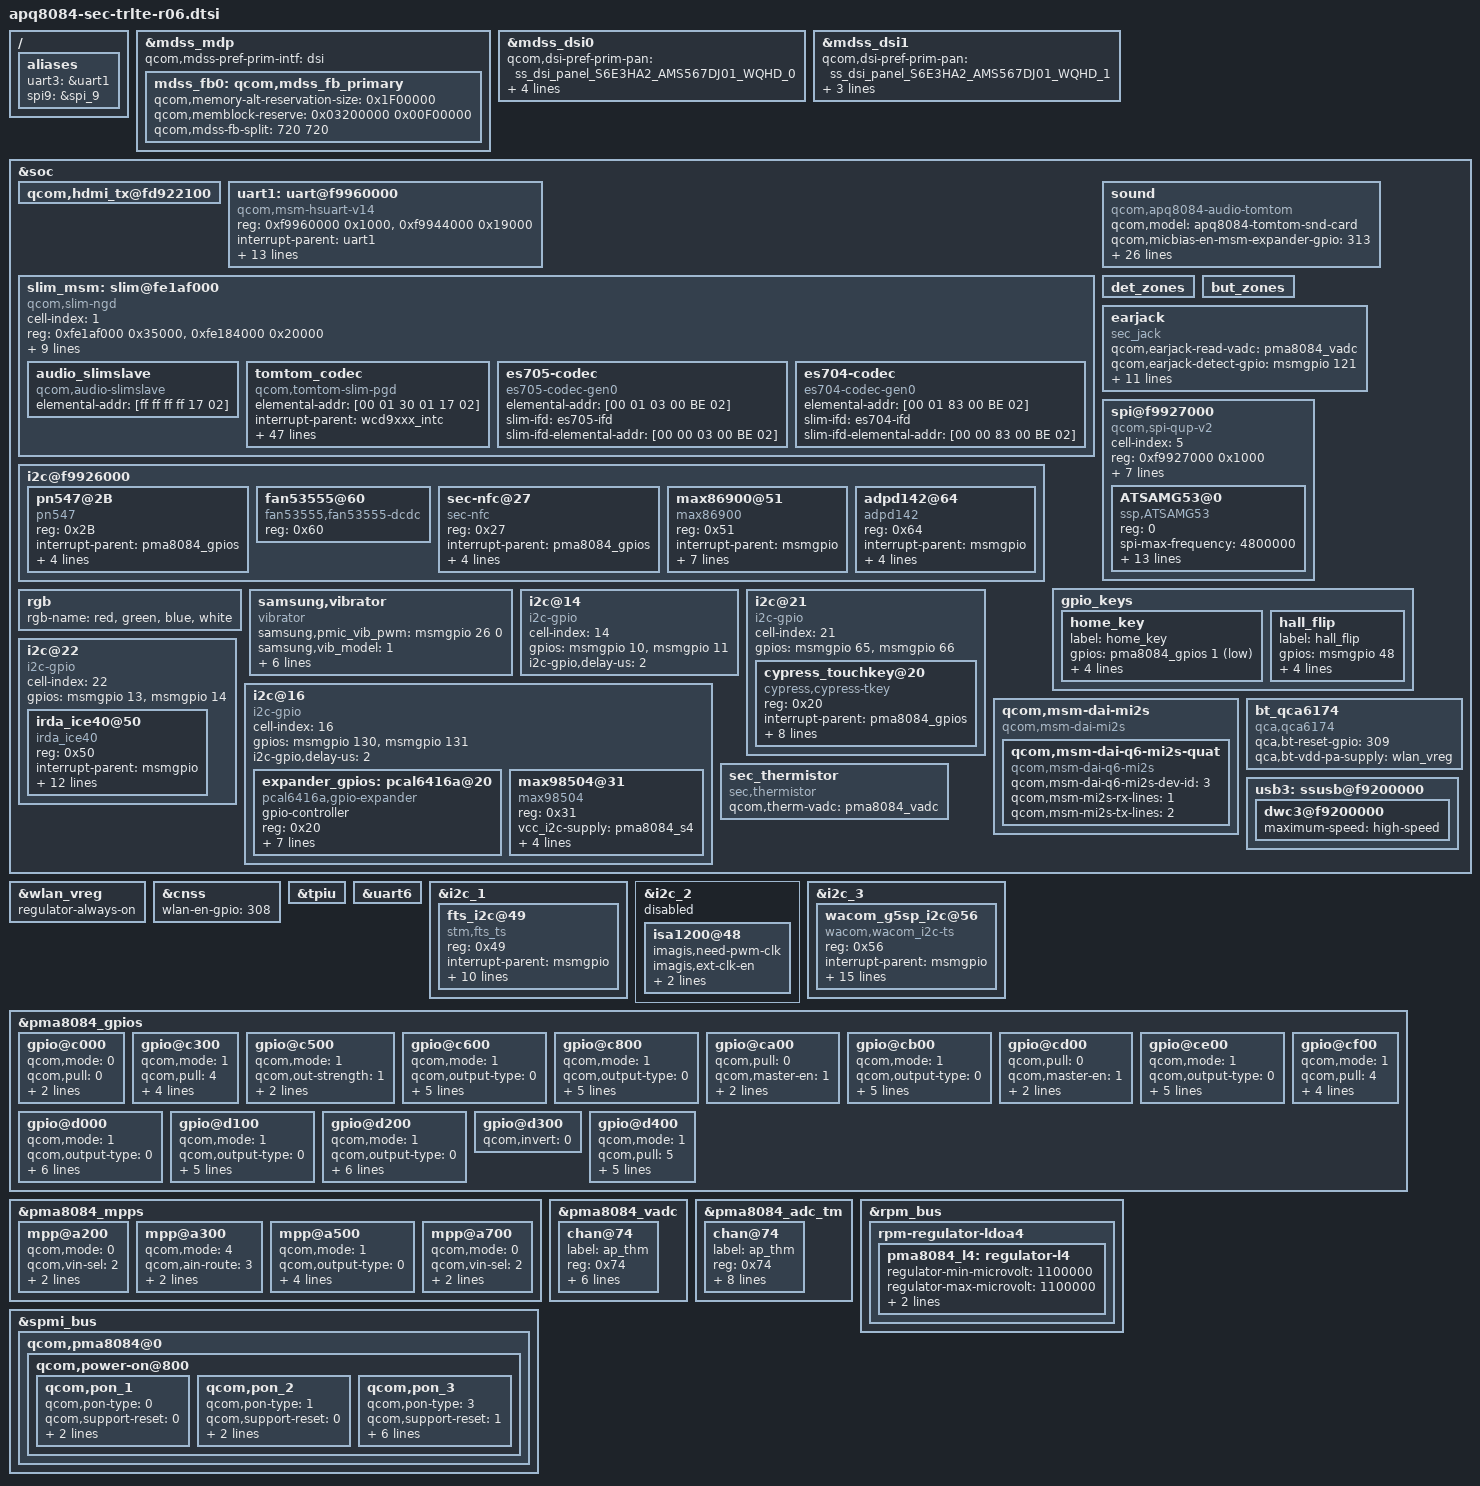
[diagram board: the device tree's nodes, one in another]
/* Copyright (c) 2013-2014, The Linux Foundation. All rights reserved.
 *
 * This program is free software; you can redistribute it and/or modify
 * it under the terms of the GNU General Public License version 2 and
 * only version 2 as published by the Free Software Foundation.
 *
 * This program is distributed in the hope that it will be useful,
 * but WITHOUT ANY WARRANTY; without even the implied warranty of
 * MERCHANTABILITY or FITNESS FOR A PARTICULAR PURPOSE.  See the
 * GNU General Public License for more details.
 */

/*
 * There are situations where removing properties or nodes may be useful.
 * syntax to do that:
 *   / {
 *       /delete-property/ propname;
 *       /delete-node/ nodename;
 *   };
 * or:
 *   /delete-node/ &noderef;
 */

#include "apq8084-camera-sensor-trlte-r04.dtsi"
#include "apq8084-max77843.dtsi"
#include "apq8084-w1-t-v1.dtsi"
#include "apq8084-fingerprint-sensor-trlte-r03.dtsi"

/ {
	aliases {
		uart3 = &uart1;
		spi9 = &spi_9;
	};
};

#include "../../../../drivers/video/msm/mdss/samsung/S6E3HA2_AMS567DJ01/dsi_panel_S6E3HA2_AMS567DJ01_wqhd_octa_cmd.dtsi"

&mdss_mdp {
		qcom,mdss-pref-prim-intf = "dsi";

		mdss_fb0: qcom,mdss_fb_primary {
			qcom,memory-alt-reservation-size = <0x1F00000>;
			qcom,memblock-reserve = <0x03200000 0x00F00000>;
			qcom,mdss-fb-split = <720 720>;
		};
	};

&mdss_dsi0 {
	qcom,dsi-pref-prim-pan = <&ss_dsi_panel_S6E3HA2_AMS567DJ01_WQHD_0>;
	qcom,platform-te-gpio = <&msmgpio 12 0>;

	/*qcom,dsi-panel-bias-vreg;*/
	qcom,platform-enable-gpio = <&pma8084_gpios 6 0>;
	qcom,platform-reset-gpio = <&pma8084_gpios 21 0>;

	iovdd-supply = <&pma8084_l26>;
};

&mdss_dsi1 {
	qcom,dsi-pref-prim-pan = <&ss_dsi_panel_S6E3HA2_AMS567DJ01_WQHD_1>;

	/*qcom,dsi-panel-bias-vreg;*/
	qcom,platform-enable-gpio = <&pma8084_gpios 6 0>;
	qcom,platform-reset-gpio = <&pma8084_gpios 21 0>;

	iovdd-supply = <&pma8084_l26>;
};

&soc {
	qcom,hdmi_tx@fd922100 {
		status = "ok";
	};

	uart1: uart@f9960000 {
		compatible = "qcom,msm-hsuart-v14";
		status = "ok";
		reg = <0xf9960000 0x1000>,
			<0xf9944000 0x19000>;
		reg-names = "core_mem", "bam_mem";
		interrupt-names = "core_irq", "bam_irq", "wakeup_irq";
	#address-cells = <0>;
		interrupt-parent = <&uart1>;
		interrupts = <0 1 2>;
	#interrupt-cells = <1>;
		interrupt-map-mask = <0xffffffff>;
		interrupt-map = <0 &intc 0 116 0 1 &intc 0 239 0 2 &msmgpio 60 0>;
		qcom,tx-gpio = <&msmgpio 59 0x00>;
		qcom,rx-gpio = <&msmgpio 60 0x00>;
		qcom,bam-tx-ep-pipe-index = <6>;
		qcom,bam-rx-ep-pipe-index = <7>;
		qcom,msm-bus,name = "uart1";
		qcom,msm-bus,num-cases = <2>;
		qcom,msm-bus,num-paths = <1>;
		qcom,msm-bus,vectors-KBps = <84 512 0 0>, <84 512 500 800>;
	};

	slim_msm: slim@fe1af000 {
		cell-index = <1>;
		compatible = "qcom,slim-ngd";
		reg = <0xfe1af000 0x35000>,
		      <0xfe184000 0x20000>;
		reg-names = "slimbus_physical", "slimbus_bam_physical";
		interrupts = <0 163 0>, <0 164 0>;
		interrupt-names = "slimbus_irq", "slimbus_bam_irq";
		qcom,apps-ch-pipes = <0x60000000>;
		qcom,ea-pc = <0xb0>;
		qcom,slim-mdm = "esoc0";

		audio_slimslave {
			compatible = "qcom,audio-slimslave";
			elemental-addr = [ff ff ff ff 17 02];
		};

		/delete-node/ taiko_codec;

		tomtom_codec {
			compatible = "qcom,tomtom-slim-pgd";
			elemental-addr = [00 01 30 01 17 02];

			interrupt-parent = <&wcd9xxx_intc>;
			interrupts = <0 1 2 3 4 5 6 7 8 9 10 11 12 13 14 15 16
				      17 18 19 20 21 22 23 24 25 26 27 28 30 31>;

			qcom,cdc-reset-gpio = <&msmgpio 101 0>;

			cdc-vdd-buck-supply = <&pma8084_s5>;
			qcom,cdc-vdd-buck-voltage = <2150000 2150000>;
			qcom,cdc-vdd-buck-current = <650000>;

			cdc-vdd-tx-h-supply = <&pma8084_s4>;
			qcom,cdc-vdd-tx-h-voltage = <1800000 1800000>;
			qcom,cdc-vdd-tx-h-current = <25000>;

			cdc-vdd-rx-h-supply = <&pma8084_s4>;
			qcom,cdc-vdd-rx-h-voltage = <1800000 1800000>;
			qcom,cdc-vdd-rx-h-current = <25000>;

			cdc-vddpx-1-supply = <&pma8084_s4>;
			qcom,cdc-vddpx-1-voltage = <1800000 1800000>;
			qcom,cdc-vddpx-1-current = <10000>;

			cdc-vdd-a-1p2v-supply = <&pma8084_l1>;
			qcom,cdc-vdd-a-1p2v-voltage = <1225000 1225000>;
			qcom,cdc-vdd-a-1p2v-current = <10000>;

			cdc-vddcx-1-supply = <&pma8084_l1>;
			qcom,cdc-vddcx-1-voltage = <1225000 1225000>;
			qcom,cdc-vddcx-1-current = <10000>;

			cdc-vddcx-2-supply = <&pma8084_l1>;
			qcom,cdc-vddcx-2-voltage = <1225000 1225000>;
			qcom,cdc-vddcx-2-current = <10000>;

			qcom,cdc-static-supplies = "cdc-vdd-buck",
						   "cdc-vdd-tx-h",
						   "cdc-vdd-rx-h",
						   "cdc-vddpx-1",
						   "cdc-vdd-a-1p2v",
						   "cdc-vddcx-1",
						   "cdc-vddcx-2";

			qcom,cdc-micbias-ldoh-v = <0x3>;
			qcom,cdc-micbias-cfilt1-mv = <1800>;
			qcom,cdc-micbias-cfilt2-mv = <2700>;
			qcom,cdc-micbias-cfilt3-mv = <1800>;
			qcom,cdc-micbias1-cfilt-sel = <0x0>;
			qcom,cdc-micbias2-cfilt-sel = <0x1>;
			qcom,cdc-micbias3-cfilt-sel = <0x2>;
			qcom,cdc-micbias4-cfilt-sel = <0x2>;
			qcom,cdc-mclk-clk-rate = <9600000>;
			qcom,cdc-slim-ifd = "tomtom-slim-ifd";
			qcom,cdc-slim-ifd-elemental-addr = [00 00 30 01 17 02];
			qcom,cdc-dmic-sample-rate = <4800000>;
			qcom,cdc-variant = "WCD9330";
		};
	};

	sound {
		compatible = "qcom,apq8084-audio-tomtom";
		qcom,model = "apq8084-tomtom-snd-card";
		qcom,micbias-en-msm-expander-gpio = <313>;

		qcom,audio-routing =
			"RX_BIAS", "MCLK",
			"LDO_H", "MCLK",
			"AIF4 MAD", "MCLK",
			"AMIC2", "MIC BIAS2 External",
			"MIC BIAS2 External", "Headset Mic",
			"DMIC1", "MIC BIAS1 External",
			"MIC BIAS1 External", "Digital Mic1",
			"DMIC2", "Main Mic Bias",
			"Main Mic Bias", "Main Mic",
			"DMIC3", "MIC BIAS3 External",
			"MIC BIAS3 External", "Digital Mic3",
			"DMIC4", "MIC BIAS1 External",
			"MIC BIAS1 External", "Sub Mic",
			"DMIC5", "MIC BIAS4 External",
			"MIC BIAS4 External", "Digital Mic5",
			"DMIC6", "MIC BIAS3 External",
			"MIC BIAS3 External", "Third Mic";

		qcom,codec-mclk-clk-freq = <9600000>;
		qcom,prim-auxpcm-gpio-clk  = <&msmgpio 87 0>;
		qcom,prim-auxpcm-gpio-sync = <&msmgpio 88 0>;
		qcom,prim-auxpcm-gpio-din  = <&msmgpio 89 0>;
		qcom,prim-auxpcm-gpio-dout = <&msmgpio 90 0>;
		qcom,prim-auxpcm-gpio-set = "prim-gpio-tert";
		qcom,sec-auxpcm-gpio-clk  = <&msmgpio 82 0>;
		qcom,sec-auxpcm-gpio-sync = <&msmgpio 83 0>;
		qcom,sec-auxpcm-gpio-dout = <&msmgpio 85 0>;
		qcom,cdc-micbias2-headset-only;
		qcom,ext-mclk-gpio  = <&msmgpio 47 0>;
		qcom,hdmi-audio-rx;
		qcom,maxim-mi2s-tx;
	};

	det_zones: det_zones {
		#list-det-cells = <4>;
	};

	but_zones: but_zones {
		#list-but-cells = <3>;
	};

	earjack {
		compatible = "sec_jack";
		qcom,earjack-read-vadc = <&pma8084_vadc>;
		qcom,earjack-detect-gpio = <&msmgpio 121 0>;
		qcom,earjack-micbias-expander-gpio = <312>;
		qcom,earjack-sendend-gpio = <&pma8084_gpios 4 0>;
		qcom,earjack-fsa_en-expander-gpio = <310>;
		qcom,send-end-active-high;
		det-zones-list = <&det_zones 3 10000 10 0>,
						 <&det_zones 930 10000 10 0>,
						 <&det_zones 2400 10000 10 1>,
						 <&det_zones 9999 10000 10 1>;
		but-zones-list = <&but_zones 0 0 145>,
						 <&but_zones 1 146 310>,
						 <&but_zones 2 311 640>;
		mpp-channel-scaling = <4 1 3>;
	};

	i2c@f9926000 { /* BLSP1 QUP4 */
		/delete-node/ nfc-nci@0e;

		pn547@2B {
			compatible = "pn547";
			reg = <0x2B>;
			interrupt-parent = <&pma8084_gpios>;
			interrupts = <11 0>;
			pn547,irq-gpio = <&pma8084_gpios 11 0>;
			pn547,ven-gpio = <&pma8084_mpps 5 0>;
			pn547,firm-expander-gpio = <311>;
		};
		fan53555@60 {
			compatible = "fan53555,fan53555-dcdc";
			reg = <0x60>;
		};

		sec-nfc@27 {
			compatible = "sec-nfc";
			reg = <0x27>;
			interrupt-parent = <&pma8084_gpios>;
			interrupts = <11 0>;
			sec-nfc,irq-gpio = <&pma8084_gpios 11 0>;
			sec-nfc,ven-gpio = <&pma8084_mpps 5 0>;
			sec-nfc,firm-expander-gpio = <311>;
		};

		max86900@51 {
			compatible = "max86900";
			reg = <0x51>;
			interrupt-parent = <&msmgpio>;
			interrupts = <78 0>;
			hrm_vreg-supply = <&pma8084_l16>;
			max86900,hrm_int-gpio = <&msmgpio 78 0x00>;
			max86900,vdd_1p8 = "max77826_ldo4";
			max86900,led_3p3 = "8084_l16";
			max86900,hrm_en-expander-gpio = <303>;
			max86900,dual-hrm = <1>;
		};

		adpd142@64 {
			compatible = "adpd142";
			reg = <0x64>;
			interrupt-parent = <&msmgpio>;
			interrupts = <78 0>;
			adpd142,irq_gpio = <&msmgpio 78 0x00>;
			adpd142,led_en = <301>;
			adpd142,vdd_1p8 = "max77826_ldo4";
		};
	};

	spi@f9927000 {
		compatible = "qcom,spi-qup-v2";
		cell-index = <5>;
		#address-cells = <1>;
		#size-cells = <0>;
		reg = <0xf9927000 0x1000>;
		interrupt-names = "spi_irq";
		interrupts = <0 99 0>;
		spi-max-frequency = <19200000>;

		qcom,gpio-mosi = <&msmgpio 39 0>;
		qcom,gpio-miso = <&msmgpio 40 0>;
		qcom,gpio-clk  = <&msmgpio 42 0>;
		qcom,gpio-cs0  = <&msmgpio 41 0>;

		qcom,master-id = <86>;

		ATSAMG53@0 {
			compatible = "ssp,ATSAMG53";
			reg = <0>;
			spi-max-frequency = <4800000>;
			interrupt-parent = <&msmgpio>;
			interrupts = <103 0>;
			ssp,mcu_int1-gpio = <&msmgpio 103 0x00>;
			ssp,mcu_int2-gpio = <&msmgpio 9 0x00>;
			ssp,ap_int-gpio = <&msmgpio 143 0x00>;
			ssp,rst-gpio = <&msmgpio 82 0x00>;
			ssp,acc-position = <3>;
			ssp,mag-position = <0>;
			ssp,prox-hi_thresh = <130>;
			ssp,prox-low_thresh = <90>;
			ssp,prox-cal_hi_thresh = <120>;
			ssp,prox-cal_low_thresh = <55>;
			ssp,ap-rev=<5>;
		};
	};

	gpio_keys {
		/delete-node/ camera_snapshot;
		/delete-node/ camera_focus;

		home_key {
			label = "home_key";
			gpios = <&pma8084_gpios 1 0x1>;
			linux,input-type = <1>;
			linux,code = <172>;
			gpio-key,wakeup;
			debounce-interval = <15>;
		};
/*
		vol_down {
			label = "volume_down";
			gpios = <&pma8084_gpios 5 0x1>;
			linux,input-type = <1>;
			linux,code = <114>;
			gpio-key,wakeup;
			debounce-interval = <15>;
		};
*/
		hall_flip {
			label = "hall_flip";
			gpios = <&msmgpio 48 0>;
			linux,input-type = <1>;
			linux,code = <21>;
			gpio-key,wakeup;
			debounce-interval = <15>;
		};
	};

	rgb {
		rgb-name = "red", "green", "blue", "white";
	};

	samsung,vibrator {
		compatible = "vibrator";
		samsung,pmic_vib_pwm = <&msmgpio 26 0>;
		samsung,vib_model = <1>;
		samsung,pmic_vib_en = <0>;
		samsung,pmic_haptic_pwr_en = <0>;
		samsung,is_pmic_vib_pwm = <0>;
		samsung,pwm_period_us = <40>;
		samsung,duty_us = <36>;
		samsung,motor_ic = <2>; /* MAX77828 : 0 , MAX77804K : 1 , MAX77843 : 2*/
		status = "ok";
	};

	i2c@14 {
		cell-index = <14>;
		compatible = "i2c-gpio";
		gpios = <&msmgpio 10 0 /* sda */
			&msmgpio 11 0 /* scl */
			>;
		i2c-gpio,delay-us = <2>;
	};

	i2c@21 {
		cell-index = <21>;
		compatible = "i2c-gpio";
		gpios = <&msmgpio 65 0 /* sda */
		&msmgpio 66 0 /* scl */
		>;
		#address-cells = <1>;
		#size-cells = <0>;

		cypress_touchkey@20 {
			compatible = "cypress,cypress-tkey";
			reg = <0x20>;
			interrupt-parent = <&pma8084_gpios>;
			interrupts = <14 0>;
			touch_3p3-supply = <&pma8084_l23>;
			vcc_en-supply = <&pma8084_lvs4>;
			cypress,scl-gpio = <&msmgpio 66 0x00>;
			cypress,sda-gpio = <&msmgpio 65 0x00>;
			cypress,irq-gpio = <&pma8084_gpios 14 0x1>;
			cypress,tkey-keycodes = <254 158>;
			cypress,i2c-pull-up = <1>;
		};
	};

	i2c@22 {
		cell-index = <22>;
		compatible = "i2c-gpio";
		gpios = <&msmgpio 13 0 /* sda */
		&msmgpio 14 0 /* scl */
		>;
		#address-cells = <1>;
		#size-cells = <0>;

		irda_ice40@50 {
			compatible = "irda_ice40";
			reg = <0x50>;
			interrupt-parent = <&msmgpio>;
			interrupts = <23 0>;
			irda_ice40,fw_ver = <2>;
			vdd-supply = <&pma8084_l16>;
			irda_ice40,gpio_fpga_main_clk = <97>;
			irda_ice40,gpio_fpga_main_clk_func = <5>;
			irda_ice40,ir_led_en_gpio = <301>;
			irda_ice40,reset_n = <&msmgpio 80 0x00>;
			irda_ice40,sda-gpio = <&msmgpio 13 0x00>;
			irda_ice40,scl-gpio = <&msmgpio 14 0x00>;
			irda_ice40,irq-gpio = <&msmgpio 23 0x00>;
			irda_ice40,cresetb = <&pma8084_gpios 9 0x1>;
			irda_ice40,i2c-pull-up = <1>;
		};
	};

	i2c@16 {
		cell-index = <16>;
		compatible = "i2c-gpio";
		gpios = <&msmgpio 130 0
			&msmgpio 131 0
			>;
		i2c-gpio,delay-us = <2>;
		#address-cells = <1>;
		#size-cells = <0>;

		expander_gpios: pcal6416a@20 {
			compatible = "pcal6416a,gpio-expander";
	                gpio-controller;
	                #gpio-cells = <2>;
			reg = <0x20>;
			pcal6416a,gpio_start = <300>;
			pcal6416a,ngpio = <16>;
			pcal6416a,reset-gpio = <&msmgpio 96 0x00>;
			pcal6416a,support_initialize = <1>;
			/* config, 15 ~ 0, 1bit configure[1:input, 0:output]*/
			pcal6416a,config = <0xA080>;    /* 1010 0000 1000 0000 */
			/* data_out, 15 ~ 0, 1bit configure[1:high, 0:low]*/
			pcal6416a,data_out = <0x0200>;	/* 0000 0010 0000 0000  */
			/* pull_reg, 31 ~ 0, 2bit configure[00:no_pull, 01:pull_down, 10:pull_up, 11:not used]*/
			pcal6416a,pull_reg = <0x00090001>; /* 00 00 00 00 / 00 00 10 01 /  00 00 00 00 / 00 00 00 01 */
		};
		max98504@31 {
			compatible = "max98504";
			reg = <0x31>;
			vcc_i2c-supply = <&pma8084_s4>;
			max98504,i2c-pull-up;
			max98504,rx_mode = <1>;
			max98504,tx_mode = <0>;
			max98504,cfg_data = <0 0 0 0 0 3 0 2 0 0>;
		};
	};

	/*# CONFIG_SND_SOC_MAX98504*/
	qcom,msm-dai-mi2s {
		compatible = "qcom,msm-dai-mi2s";
		qcom,msm-dai-q6-mi2s-quat {
			compatible = "qcom,msm-dai-q6-mi2s";
			qcom,msm-dai-q6-mi2s-dev-id = <3>;
			qcom,msm-mi2s-rx-lines = <1>;
			qcom,msm-mi2s-tx-lines = <2>;
		};
	};

	sec_thermistor {
		compatible = "sec,thermistor";
		qcom,therm-vadc = <&pma8084_vadc>;
	};

	bt_qca6174 {
		compatible = "qca,qca6174";
		qca,bt-reset-gpio = <309>; /* BT_EN */
		qca,bt-vdd-pa-supply = <&wlan_vreg>;
/*		qca,bt-vdd-ldo-supply = <&pma8084_l27>;*/
/*		qca,bt-vdd-ldo-voltage-level = <1150000 1150000>;*/
	};

	usb3: ssusb@f9200000 {
	   dwc3@f9200000 {
		   maximum-speed = "high-speed";
	   };
	};
};

&wlan_vreg {
	regulator-always-on;
};

&cnss {
	wlan-en-gpio = <308>;
};

&tpiu {
	/delete-property/ qcom,seta-gpios;
	/delete-property/ qcom,seta-gpios-func;
	/delete-property/ qcom,seta-gpios-drv;
	/delete-property/ qcom,seta-gpios-pull;
	/delete-property/ qcom,seta-gpios-dir;

	/delete-property/ qcom,setb-gpios;
	/delete-property/ qcom,setb-gpios-func;
	/delete-property/ qcom,setb-gpios-drv;
	/delete-property/ qcom,setb-gpios-pull;
	/delete-property/ qcom,setb-gpios-dir;
};

&uart6 {
	status = "ok";
};

&slim_msm {
	tomtom_codec {
		qcom,cdc-micbias1-ext-cap;
		qcom,cdc-micbias3-ext-cap;

		/*
		 * spkrdrv supply in MTP device is from VPH_PWR which is
		 * always ON. Give a dummy supply to make codec driver happy.
		 */
		cdc-vdd-spkdrv-supply = <&vph_pwr_vreg>;
		qcom,cdc-vdd-spkdrv-voltage = <0 0>;
		qcom,cdc-vdd-spkdrv-current = <0>;

		qcom,cdc-on-demand-supplies = "cdc-vdd-spkdrv";
	};
};

&slim_msm {
	es705-gpioa-gpio = <&msmgpio 91 0>;
	es705-gpiob-gpio = <&msmgpio 76 0>;
	es705-uart-tx = <&msmgpio 59 0>;
	es705-uart-rx = <&msmgpio 60 0>;
	es705-reset-expander-gpio = <300>;

	es705-codec {
		compatible = "es705-codec-gen0";
		elemental-addr = [00 01 03 00 BE 02];
		slim-ifd = "es705-ifd";
		slim-ifd-elemental-addr = [00 00 03 00 BE 02];
	};

	es704-codec {
		compatible = "es704-codec-gen0";
		elemental-addr = [00 01 83 00 BE 02];
		slim-ifd = "es704-ifd";
		slim-ifd-elemental-addr = [00 00 83 00 BE 02];
	};
};

&i2c_1 {
	status = "okay";
	/delete-node/ synaptics@20;

	fts_i2c@49 {
		compatible = "stm,fts_ts";
		reg = <0x49>;
		interrupt-parent = <&msmgpio>;
		interrupts = <79 0>;
		vcc_en-supply = <&pma8084_lvs3>;
		stm,supply-num = <2>;		// the number of regulators
		stm,supply-name = "8084_l17", "8084_lvs3";	// the name of regulators, in power-on order
		stm,irq-gpio = <&msmgpio 79 0x1>;
		stm,tsp-coords = <1439 2559>;
		stm,support_func = <1 1>; // <support_hover, support_mshover>
		stm,i2c-pull-up = <1>;
		stm,tsp-project = "TR_LTE";
		stm,tsp-extra_config = <0 0 0 0>;// <"pwrctrl", "pwrctrl(sub)", "octa_id", "N">
	};
};

&i2c_2 {
	status = "disabled";
	isa1200@48 {
		/delete-property/ imagis,is-erm;
		imagis,need-pwm-clk;
		imagis,ext-clk-en;
		imagis,pwm-div = <256>;
		imagis,mode-ctrl = <2>;
	};
};

&i2c_3  { /* BLSP2 QUP6 */

	status = "okay";

	wacom_g5sp_i2c@56 {
		compatible = "wacom,wacom_i2c-ts";
		reg = <0x56>;
		interrupt-parent = <&msmgpio>;
		interrupts = <24 0>;
		/* vdd_en-gpio = <&msmgpio 136 0x1>; */
		vcc_en-supply = <&pma8084_l18>;
		wacom,scl-gpio = <&msmgpio 50 0x00>;
		wacom,sda-gpio = <&msmgpio 49 0x00>;
		/* wacom,reset_n-gpio = <&msmgpio 72 0x00>; */
		wacom,pen_fwe1-gpio = <&msmgpio 16 0x00>;
		wacom,pen_pdct-gpio = <&msmgpio 81 0x00>;
		wacom,sense-gpio = <&pma8084_mpps 3 0x0>;
		wacom,irq-gpio = <&msmgpio 24 0x00>;
		wacom,panel-coords = <1 0 0 12544 0 7056 1 0 2047>;
		wacom,i2c-pull-up = <1>;
		wacom,basic_model = "TR_LTE";
		wacom,irq_flags = <0x3>;
		wacom,ic_mpu_ver = <0x2D>;
		wacom,firmup_flag = <1>;
	};
};


&pma8084_gpios {
	gpio@c000 { /* GPIO 1 */
		qcom,mode = <0>;
		qcom,pull = <0>;
		qcom,vin-sel = <2>;
		qcom,src-sel = <0>;
	};
	gpio@c300 { /* GPIO 4 */
                qcom,mode = <1>;         /* Digital output*/
                qcom,pull = <4>;         /* Pulldown 10uA */
                qcom,vin-sel = <2>;      /* VIN2 */
                qcom,src-sel = <0>;      /* GPIO */
                qcom,invert = <0>;       /* Invert */
                qcom,master-en = <1>;    /* Enable GPIO */
	};
	gpio@c500 { /* GPIO 6 */
		/* LCD_EN */
		qcom,mode = <1>;		/* Digital output */
		qcom,out-strength = <1>;	/* Low */
		qcom,src-sel = <0>;		/* Function 1  */
		qcom,master-en = <1>;
	};

	gpio@c600 { /* GPIO 7 */
		qcom,mode = <1>;		/* Digital output */
		qcom,output-type = <0>;		/* CMOS logic */
		qcom,invert = <0>;		/* Output low initially */
		qcom,vin-sel = <2>;		/* VIN 2 */
		qcom,src-sel = <0>;		/* GPIO */
		qcom,out-strength = <3>;	/* HIGH */
		qcom,master-en = <1>;		/* Enable GPIO */
	};

	gpio@c800 { /* GPIO 9 */
		qcom,mode = <1>;		/* Digital output */
		qcom,output-type = <0>;		/* CMOS logic */
		qcom,invert = <0>;		/* Do not invert the output */
		qcom,vin-sel = <2>;		/* PMA8084 S4 = 1.8 V */
		qcom,src-sel = <0>;		/* GPIO */
		qcom,out-strength = <3>;	/* High drive strength */
		qcom,master-en = <1>;		/* Enable GPIO */
	};
	gpio@ca00 { /* GPIO 11 */
		qcom,pull = <0>;		/* set to default pull */
		qcom,master-en = <1>;
		qcom,vin-sel = <2>;		/* select 1.8 V source */
		qcom,src-sel = <3>;
	};
	gpio@cb00 { /* GPIO 12 */
		qcom,mode = <1>;		/* Digital output */
		qcom,output-type = <0>;		/* CMOS logic */
		qcom,invert = <0>;		/* Output low initially */
		qcom,vin-sel = <2>;		/* VIN 2 */
		qcom,src-sel = <0>;		/* GPIO */
		qcom,out-strength = <2>;	/* Medium */
		qcom,master-en = <1>;		/* Enable GPIO */
	};

	gpio@cd00 { /* GPIO 14 */
		/delete-property/ qcom,mode;
		qcom,pull = <0>;		/* set to default pull */
		qcom,master-en = <1>;
		qcom,vin-sel = <2>;		/* select 1.8 V source */
		qcom,src-sel = <3>;
	};
	gpio@ce00 { /* GPIO 15 */
		qcom,mode = <1>;		/* Digital output */
		qcom,output-type = <0>;		/* CMOS logic */
		qcom,invert = <0>;		/* Output low initially */
		qcom,vin-sel = <2>;		/* VIN 2 */
		qcom,src-sel = <2>;		/* Function 1 */
		qcom,out-strength = <3>;	/* High */
		qcom,master-en = <1>;		/* Enable GPIO */
	};

	gpio@cf00 { /* GPIO 16 */
		qcom,mode = <1>;		/* Digital output*/
		/delete-property/ qcom,output-type;
		qcom,pull = <4>;		/* Pulldown 10uA */
		qcom,vin-sel = <2>;		/* VIN2 */
		/delete-property/ qcom,out-strength;
		qcom,src-sel = <0>;		/* GPIO */
		qcom,invert = <0>;		/* Invert */
		qcom,master-en = <1>;		/* Enable GPIO */
	};

	gpio@d000 { /* GPIO 17 */
		qcom,mode = <1>;		/* Digital output*/
		qcom,output-type = <0>;	/* CMOS logic */
		qcom,pull = <4>;		/* Pulldown 10uA */
		qcom,vin-sel = <2>;		/* VIN2 */
		qcom,out-strength = <2>;	/* Medium drive strength */
		qcom,src-sel = <0>;		/* GPIO */
		qcom,invert = <0>;		/* Invert */
		qcom,master-en = <1>;		/* Enable GPIO */
	};

	gpio@d100 { /* GPIO 18 used for BT/WiFi sleep_clk */
		qcom,mode = <1>;		/* Digital output*/
		qcom,output-type = <0>;	/* CMOS logic */
		qcom,pull = <5>;		/* QPNP_PIN_PULL_NO */
		qcom,vin-sel = <2>;		/* VIN2 */
		qcom,out-strength = <3>;	/* Medium drive strength */
		qcom,src-sel = <3>;		/* GPIO */
		qcom,master-en = <1>;		/* Enable GPIO */
	};

	gpio@d200 { /* GPIO 19 */
		qcom,mode = <1>;		/* Digital output */
		qcom,output-type = <0>;	/* CMOS logic */
		qcom,pull = <5>;			/* QPNP_PIN_PULL_NO */
		qcom,invert = <0>;		/* Output low initially */
		qcom,vin-sel = <2>;		/* PM8941 S3 = 1.8 V */
		qcom,src-sel = <0>;		/* Constant */
		qcom,out-strength = <2>;	/* Medium drive strength */
		qcom,master-en = <1>;	/* Enable GPIO */
	};

	gpio@d300 { /* GPIO 20 */
		qcom,invert = <0>;		/* Do not invert the output */
	};

	gpio@d400 { /* GPIO 21 */
		/* LCD_RESET */
		qcom,mode = <1>;		/* Digital output */
		qcom,pull = <5>;		/* Pull down */
		qcom,output-type = <0>;		/* CMOS */
		qcom,vin-sel = <2>;		/* PMA8084 S4 = 1.8 V */
		qcom,out-strength = <1>;	/* Low */
		qcom,src-sel = <0>;		/* constant */
		qcom,master-en = <1>;
	};

};

&pma8084_mpps {

	mpp@a200 { /* MPP 3 */
		/* wacom sense gpio */
		qcom,mode = <0>;		/* Digital input */
		qcom,vin-sel = <2>;
		qcom,src-sel = <0>;		/* Constant */
		qcom,master-en = <1>;		/* Enable GPIO */
	};

	mpp@a300 { /* MPP 4 */
		qcom,mode = <4>; /* AIN input */
		qcom,ain-route = <3>; /* AMUX 8 */
		qcom,master-en = <1>;/* Enable MPP4 */
		qcom,src-sel = <0>; /* Function constant */
	};

	mpp@a500 { /* MPP 6 */
		qcom,mode = <1>;                /* Digital output */
		qcom,output-type = <0>;         /* CMOS */
		qcom,vin-sel = <2>;             /* PMA8084 S4 = 1.8V > 1.6V */
		qcom,src-sel = <0>;             /* Constant */
		/*qcom,out-strength = <1>;*/      /* Low */
		qcom,master-en = <1>;
		qcom,invert = <0>;		/* Invert */
	};

	mpp@a700 { /* MPP 8 */
		qcom,mode = <0>; /* DIG_IN */
		qcom,vin-sel = <2>; /* PMA8084_S3 1.8V > 1.6V */
		qcom,src-sel = <0>; /* CONSTANT */
		qcom,master-en = <1>; /* ENABLE MPP */
	};
};

&pma8084_vadc {
	chan@74 {
		label = "ap_thm";
		reg = <0x74>;
		qcom,decimation = <0>;
		qcom,pre-div-channel-scaling = <0>;
		qcom,calibration-type = "ratiometric";
		qcom,scale-function = <2>;
		qcom,hw-settle-time = <2>;
		qcom,fast-avg-setup = <0>;
	};
};

&pma8084_adc_tm {
	chan@74 {
		label = "ap_thm";
		reg = <0x74>;
		qcom,decimation = <0>;
		qcom,pre-div-channel-scaling = <0>;
		qcom,calibration-type = "ratiometric";
		qcom,scale-function = <2>;
		qcom,hw-settle-time = <2>;
		qcom,fast-avg-setup = <3>;
		qcom,btm-channel-number = <0x69>;
		qcom,thermal-node;
	};
};
/* RPM controlled regulators: */
&rpm_bus {
	rpm-regulator-ldoa4 {
		status = "okay";
		pma8084_l4: regulator-l4 {
			regulator-min-microvolt = <1100000>;
			regulator-max-microvolt = <1100000>;
			qcom,init-voltage = <1100000>;
			status = "okay";
			regulator-always-on;
		};
	};
};

&spmi_bus {
	qcom,pma8084@0 {
		qcom,power-on@800 {
			qcom,pon_1 {
				qcom,pon-type = <0>;
				qcom,support-reset = <0>;
				qcom,pull-up = <1>;
				linux,code = <116>;
			};

			qcom,pon_2 {
				qcom,pon-type = <1>;
				qcom,support-reset = <0>;
				qcom,pull-up = <1>;
				linux,code = <114>;
			};

			qcom,pon_3 {
				qcom,pon-type = <3>;
				qcom,support-reset = <1>;
				qcom,s1-timer = <6720>;
				qcom,s2-timer = <1000>;
				qcom,s1-timer2 = <10256>;
				qcom,s2-timer2 = <100>;
				qcom,s2-type = <1>;
				qcom,pull-up = <1>;
			};
		};
	};
};

